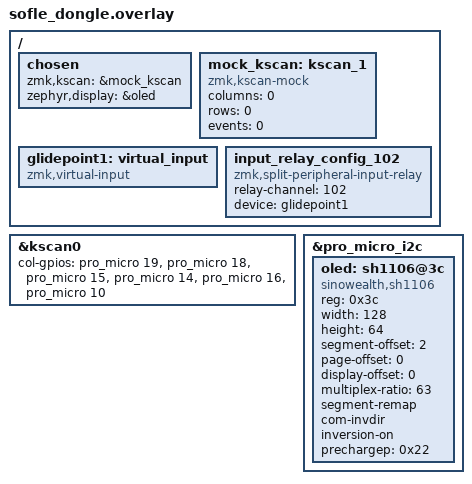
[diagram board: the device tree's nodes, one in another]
#include "sofle.dtsi"
#include "sofle_cirque.dtsi"

/ {
    chosen {
        zmk,kscan = &mock_kscan;
        zephyr,display = &oled;
    };

    mock_kscan: kscan_1 {
        compatible = "zmk,kscan-mock";
        columns = <0>;
        rows = <0>;
        events = <0>;
    };
};

&kscan0 {
    col-gpios
        = <&pro_micro 19 GPIO_ACTIVE_HIGH>
        , <&pro_micro 18 GPIO_ACTIVE_HIGH>
        , <&pro_micro 15 GPIO_ACTIVE_HIGH>
        , <&pro_micro 14 GPIO_ACTIVE_HIGH>
        , <&pro_micro 16 GPIO_ACTIVE_HIGH>
        , <&pro_micro 10 GPIO_ACTIVE_HIGH>
        ;
};

&pro_micro_i2c {
    status = "okay";
    oled: sh1106@3c {
        compatible = "sinowealth,sh1106";
        reg = <0x3c>;
        width = <128>;
        height = <64>;
        segment-offset = <2>;
        page-offset = <0>;
        display-offset = <0>;
        multiplex-ratio = <63>;
        segment-remap;
        com-invdir;
        inversion-on;
        prechargep = <0x22>;
    };
};

// Cirque Trackpad
// Split peripheral input relay module central.
/ {
	glidepoint1: virtual_input {
		compatible = "zmk,virtual-input";
	};

	input_relay_config_102 {
		compatible = "zmk,split-peripheral-input-relay";
		relay-channel = <102>;
		device = <&glidepoint1>;
	};
};
